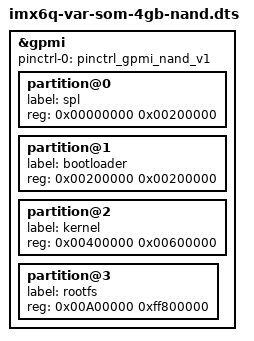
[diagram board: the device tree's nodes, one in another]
/*
 * Copyright 2012 Freescale Semiconductor, Inc.
 * Copyright 2011 Linaro Ltd.
 *
 * The code contained herein is licensed under the GNU General Public
 * License. You may obtain a copy of the GNU General Public License
 * Version 2 or later at the following locations:
 *
 * http://www.opensource.org/licenses/gpl-license.html
 * http://www.gnu.org/copyleft/gpl.html
 */


#include "imx6q-var-som.dts"

&gpmi {
	pinctrl-names = "default";
	pinctrl-0 = <&pinctrl_gpmi_nand_v1>;
	status = "okay";

	partition@0 {
		label = "spl";
		reg = <0x00000000 0x00200000>;
	};

	partition@1 {
		label = "bootloader";
		reg = <0x00200000 0x00200000>;
	};


	partition@2 {
		label = "kernel";
		reg = <0x00400000 0x00600000>;
	};

	partition@3 {
		label = "rootfs";
		reg = <0x00A00000 0xff800000>;
	};

};

